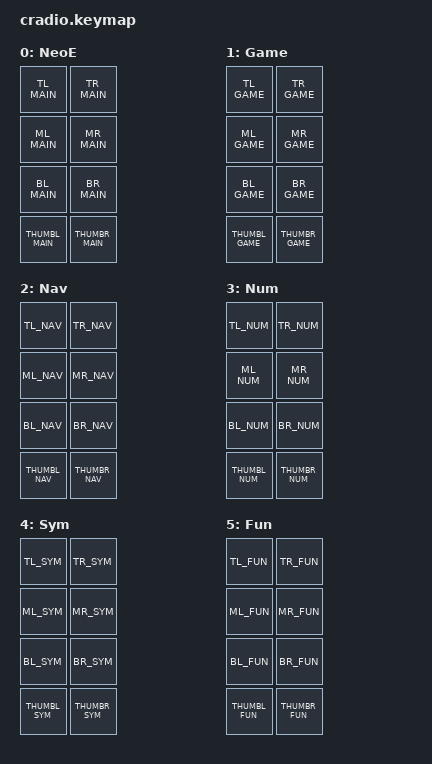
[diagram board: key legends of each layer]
#include <behaviors.dtsi>
#include <reset_all.dtsi>
#include <dt-bindings/zmk/keys.h>
#include <dt-bindings/zmk/bt.h>
#include <dt-bindings/zmk/outputs.h>

#include "zmk-helpers/helper.h"
#include "zmk-helpers/key-labels/34.h"

#include "merlinvn/config.dtsi"

// Behaviors depend on config definitions; combos and keymap depend on behaviors.
#include "merlinvn/macros.dtsi"
#include "merlinvn/behaviors.dtsi"
#define RESET_BEHAVIOR &reset_all
#define CLEAR_COMBO_BINDING &reset_all
#include "merlinvn/combos.dtsi"
#include "merlinvn/keymap.dtsi"

/ {
    keymap {
        compatible = "zmk,keymap";

        neo_layer {
            display-name = "NeoE";
            bindings = <
                TL_MAIN TR_MAIN
                ML_MAIN MR_MAIN
                BL_MAIN BR_MAIN
                THUMBL_MAIN THUMBR_MAIN
            >;
        };

        game_layer {
            display-name = "Game";
            bindings = < TL_GAME TR_GAME ML_GAME MR_GAME BL_GAME BR_GAME THUMBL_GAME THUMBR_GAME >;
        };

        nav_layer {
            display-name = "Nav";
            bindings = < TL_NAV TR_NAV ML_NAV MR_NAV BL_NAV BR_NAV THUMBL_NAV THUMBR_NAV >;
        };

        num_layer {
            display-name = "Num";
            bindings = < TL_NUM TR_NUM ML_NUM MR_NUM BL_NUM BR_NUM THUMBL_NUM THUMBR_NUM >;
        };

        sym_layer {
            display-name = "Sym";
            bindings = < TL_SYM TR_SYM ML_SYM MR_SYM BL_SYM BR_SYM THUMBL_SYM THUMBR_SYM >;
        };

        fun_layer {
            display-name = "Fun";
            bindings = < TL_FUN TR_FUN ML_FUN MR_FUN BL_FUN BR_FUN THUMBL_FUN THUMBR_FUN >;
        };

    };
};
